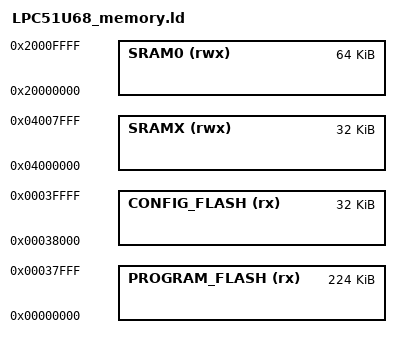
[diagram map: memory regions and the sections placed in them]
/*
 * GENERATED FILE - DO NOT EDIT
 * Copyright (c) 2008-2013 Code Red Technologies Ltd,
 * Copyright 2015, 2018-2019 NXP
 * (c) NXP Semiconductors 2013-2021
 * Generated linker script file for LPC51U68
 * Created from memory.ldt by FMCreateLinkMemory
 * Using Freemarker v2.3.23
 * MCUXpresso IDE v11.2.1 [Build 4149] [2020-10-07] on 02/01/2021 11:02:27
 */

MEMORY
{
  /* Define each memory region */
  PROGRAM_FLASH (rx) : ORIGIN = 0x0, 	 LENGTH = 0x38000 /* 224K bytes (alias Flash) */  
  CONFIG_FLASH  (rx) : ORIGIN = 0x38000, LENGTH = 0x8000  /* 32K bytes */
  SRAM0 (rwx) : ORIGIN = 0x20000000, LENGTH = 0x10000 /* 64K bytes (alias RAM) */  
  SRAMX (rwx) : ORIGIN = 0x4000000, LENGTH = 0x8000 /* 32K bytes (alias RAM2) */  
}

  /* Define a symbol for the top of each memory region */
  __base_PROGRAM_FLASH = 0x0  ; /* PROGRAM_FLASH */  
  __base_Flash = 0x0 ; /* Flash */  
  __top_PROGRAM_FLASH = 0x0 + 0x40000 ; /* 256K bytes */  
  __top_Flash = 0x0 + 0x40000 ; /* 256K bytes */  
  __base_SRAM0 = 0x20000000  ; /* SRAM0 */  
  __base_RAM = 0x20000000 ; /* RAM */  
  __top_SRAM0 = 0x20000000 + 0x10000 ; /* 64K bytes */  
  __top_RAM = 0x20000000 + 0x10000 ; /* 64K bytes */  
  __base_SRAMX = 0x4000000  ; /* SRAMX */  
  __base_RAM2 = 0x4000000 ; /* RAM2 */  
  __top_SRAMX = 0x4000000 + 0x8000 ; /* 32K bytes */  
  __top_RAM2 = 0x4000000 + 0x8000 ; /* 32K bytes */  
